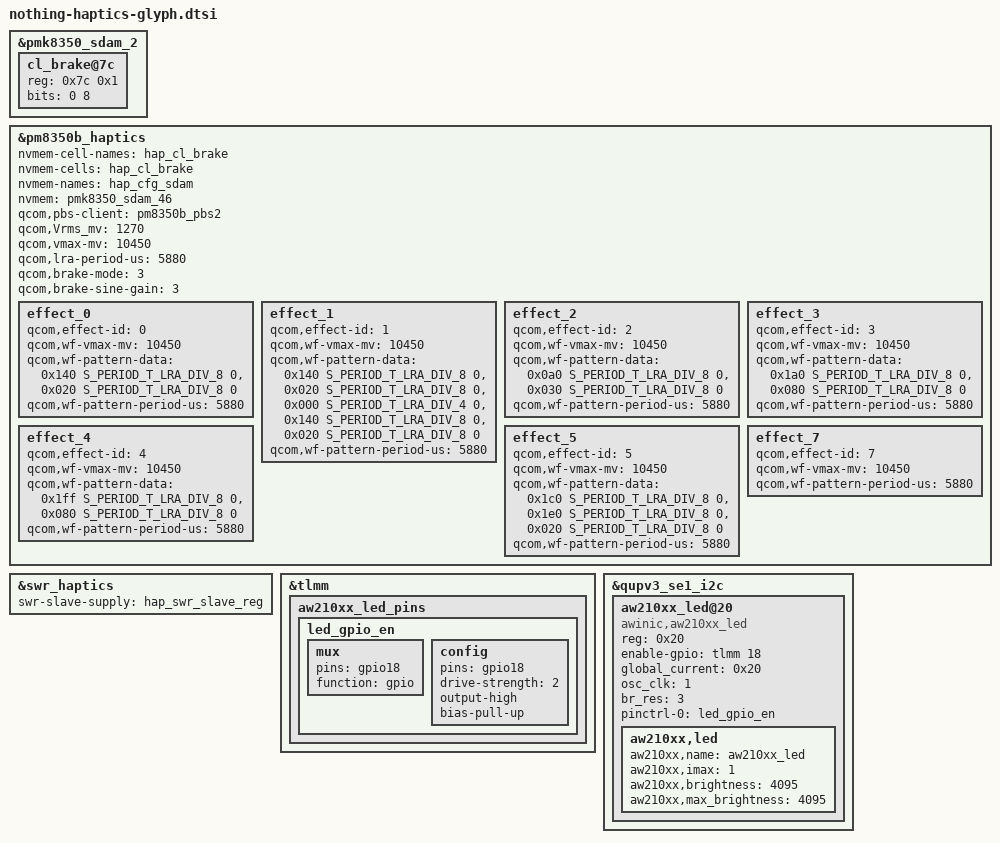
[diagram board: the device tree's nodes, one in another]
/*
 * Nothing/Spacewar-specific haptics and Glyph LED overrides.
 *
 * Copies of the blocks already defined in yupik-qrd.dtsi -- yupik-qrd.dtsi
 * stays untouched. Devicetree overlay merge is last-include-wins per
 * property, so anything redeclared here (after yupik-qrd.dtsi in the
 * #include chain) overrides the base value. Properties left out of a
 * redeclared node still inherit from yupik-qrd.dtsi.
 */

&pmk8350_sdam_2 {
	cl_brake@7c {
		reg = <0x7c 0x1>;
		bits = <0 8>;
	};
};

&pm8350b_haptics {
	nvmem-cell-names = "hap_cl_brake";
	nvmem-cells = <&hap_cl_brake>;
	nvmem-names = "hap_cfg_sdam";
	nvmem = <&pmk8350_sdam_46>;
	qcom,pbs-client = <&pm8350b_pbs2>;


	qcom,Vrms_mv = <1270>;
	qcom,vmax-mv = <10450>;
	qcom,lra-period-us = <5880>;
	status = "ok";

	qcom,brake-mode = <3>; /* AUTO_BRAKE */
	qcom,brake-sine-gain = <3>; /* BRAKE_SINE_GAIN_X8, was X4 */


	effect_0 {
		/* CLICK -- short, clean single snap. General-purpose (most
		 * UI touches route here); framework's UDFPS-success routing
		 * moved off this to POP (effect_4), see frameworks/base.
		 */
		qcom,effect-id = <0>;
		qcom,wf-vmax-mv = <10450>;
		qcom,wf-pattern-data = <0x140 S_PERIOD_T_LRA_DIV_8 0>,
					<0x020 S_PERIOD_T_LRA_DIV_8 0>;
		qcom,wf-pattern-period-us = <5880>;
	};

	effect_1 {
		/* DOUBLE_CLICK ("ti-tick") -- two short pulses with a real
		 * silent gap between them, not one blob. This is what
		 * BIOMETRIC_REJECT (UDFPS auth failure) actually plays.
		 */
		qcom,effect-id = <1>;
		qcom,wf-vmax-mv = <10450>;
		qcom,wf-pattern-data = <0x140 S_PERIOD_T_LRA_DIV_8 0>,
					<0x020 S_PERIOD_T_LRA_DIV_8 0>,
					<0x000 S_PERIOD_T_LRA_DIV_4 0>,
					<0x140 S_PERIOD_T_LRA_DIV_8 0>,
					<0x020 S_PERIOD_T_LRA_DIV_8 0>;
		qcom,wf-pattern-period-us = <5880>;
	};

	effect_2 {
		/* TICK -- lightest, briefest, barely-there tap. Same
		 * ceiling as the others now; lightness comes from the low
		 * amplitude codes and short duration in the pattern below.
		 */
		qcom,effect-id = <2>;
		qcom,wf-vmax-mv = <10450>;
		qcom,wf-pattern-data = <0x0a0 S_PERIOD_T_LRA_DIV_8 0>,
					<0x030 S_PERIOD_T_LRA_DIV_8 0>;
		qcom,wf-pattern-period-us = <5880>;
	};

	effect_3 {
		/* THUD -- was long T_LRA/T_LRA_X_2 periods for a deliberate
		 * "heavy" feel; now DIV_8 like everything else per explicit
		 * "tightest across the board" request. Weight now comes only
		 * from the two-step peak-then-sustain amplitude shape, not
		 * from timing.
		 */
		qcom,effect-id = <3>;
		qcom,wf-vmax-mv = <10450>;
		qcom,wf-pattern-data = <0x1a0 S_PERIOD_T_LRA_DIV_8 0>,
					<0x080 S_PERIOD_T_LRA_DIV_8 0>;
		qcom,wf-pattern-period-us = <5880>;
	};

	effect_4 {
		/* POP -- sharp, punchy, brief spike-then-decay. Now also
		 * what BIOMETRIC_CONFIRM (UDFPS auth success) plays,
		 * routed here in frameworks/base's HapticFeedbackVibration-
		 * Provider instead of falling through to generic CLICK.
		 */
		qcom,effect-id = <4>;
		qcom,wf-vmax-mv = <10450>;
		qcom,wf-pattern-data = <0x1ff S_PERIOD_T_LRA_DIV_8 0>,
					<0x080 S_PERIOD_T_LRA_DIV_8 0>;
		qcom,wf-pattern-period-us = <5880>;
	};

	effect_5 {
		/* HEAVY CLICK -- strongest single click: higher peak and
		 * one more step of sustain than CLICK, same ceiling as the
		 * others but the fullest use of it.
		 */
		qcom,effect-id = <5>;
		qcom,wf-vmax-mv = <10450>;
		qcom,wf-pattern-data = <0x1c0 S_PERIOD_T_LRA_DIV_8 0>,
					<0x1e0 S_PERIOD_T_LRA_DIV_8 0>,
					<0x020 S_PERIOD_T_LRA_DIV_8 0>;
		qcom,wf-pattern-period-us = <5880>;
	};

	effect_7 {
		/* FIFO sample only, not one of the six canned Effect-enum
		 * IDs. Raised to the same 10450 ceiling as the others,
		 * still under MAX_VMAX_MV (11000).
		 */
		qcom,effect-id = <7>;
		qcom,wf-vmax-mv = <10450>;
		qcom,wf-pattern-period-us = <5880>;
	};
};

&swr_haptics {
	status = "okay";
	swr-slave-supply = <&hap_swr_slave_reg>;
};

&tlmm {
	aw210xx_led_pins {
		led_gpio_en {
			mux {
				pins = "gpio18";
				function = "gpio";
			};

			config {
				pins = "gpio18";
				drive-strength = <2>;
				output-high;
				bias-pull-up;
			};
		};
	};
};

&qupv3_se1_i2c {
	status = "ok";
	aw210xx_led@20 {
		compatible = "awinic,aw210xx_led";
		reg = <0x20>;
		enable-gpio = <&tlmm 18 0x00>;
		global_current = <0x20>;
		osc_clk = <1>;
		br_res = <3>;
		pinctrl-names = "default";
		pinctrl-0 = <&led_gpio_en>;
		status = "ok";
		aw210xx,led {
			aw210xx,name = "aw210xx_led";
			aw210xx,imax = <1>;
			aw210xx,brightness = <4095>;
			aw210xx,max_brightness = <4095>;
		};
	};
};
